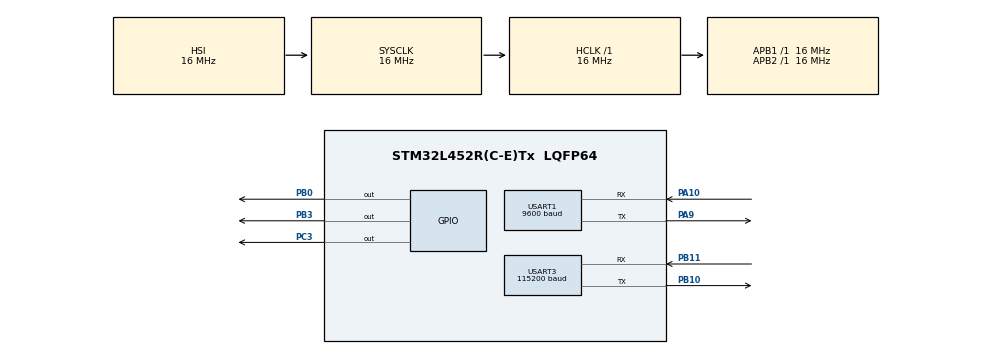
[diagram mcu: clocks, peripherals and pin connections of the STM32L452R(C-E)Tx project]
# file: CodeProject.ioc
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Mcu.Family=STM32L4
Mcu.Name=STM32L452R(C-E)Tx
Mcu.Package=LQFP64
NVIC.PriorityGroup=NVIC_PRIORITYGROUP_4
NVIC.TIM2_IRQn=true\:0\:0\:false\:false\:true\:true\:true
NVIC.USART1_IRQn=true\:0\:0\:false\:false\:true\:true\:true
NVIC.USART3_IRQn=true\:0\:0\:false\:false\:true\:true\:true
PA10.Mode=Asynchronous
PA10.Signal=USART1_RX
PA13\ (JTMS/SWDIO).Mode=Serial_Wire
PA13\ (JTMS/SWDIO).Signal=SYS_JTMS-SWDIO
PA14\ (JTCK/SWCLK).Mode=Serial_Wire
PA14\ (JTCK/SWCLK).Signal=SYS_JTCK-SWCLK
PA9.Mode=Asynchronous
PA9.Signal=USART1_TX
PB0.Signal=GPIO_Output
PB10.Mode=Asynchronous
PB10.Signal=USART3_TX
PB11.Mode=Asynchronous
PB11.Signal=USART3_RX
PB3\ (JTDO/TRACESWO).Signal=GPIO_Output
PC14-OSC32_IN\ (PC14).Mode=LSE-External-Oscillator
PC14-OSC32_IN\ (PC14).Signal=RCC_OSC32_IN
PC15-OSC32_OUT\ (PC15).Mode=LSE-External-Oscillator
PC15-OSC32_OUT\ (PC15).Signal=RCC_OSC32_OUT
PC3.Signal=GPIO_Output
ProjectManager.HeapSize=0x200
ProjectManager.StackSize=0x400
ProjectManager.TargetToolchain=STM32CubeIDE
RCC.ADCFreq_Value=64000000
RCC.AHBFreq_Value=16000000
RCC.APB1Freq_Value=16000000
RCC.APB1TimFreq_Value=16000000
RCC.APB2Freq_Value=16000000
RCC.APB2TimFreq_Value=16000000
RCC.CortexFreq_Value=16000000
RCC.HCLKFreq_Value=16000000
RCC.HSE_VALUE=8000000
RCC.HSI48_VALUE=48000000
RCC.HSI_VALUE=16000000
RCC.MSIClockRange=RCC_MSIRANGE_8
RCC.MSI_VALUE=16000000
RCC.PLLSourceVirtual=RCC_PLLSOURCE_HSI
RCC.RTCClockSelection=RCC_RTCCLKSOURCE_LSE
RCC.SYSCLKFreq_VALUE=16000000
RCC.SYSCLKSource=RCC_SYSCLKSOURCE_HSI
RCC.USBFreq_Value=64000000
RCC.VCOOutputFreq_Value=128000000
RTC.SynchPrediv=255
TIM2.Period=999
TIM2.Prescaler=15
USART1.BaudRate=9600
USART1.VirtualMode-Asynchronous=VM_ASYNC
USART3.BaudRate=115200
USART3.VirtualMode-Asynchronous=VM_ASYNC
VP_RTC_VS_RTC_Activate.Mode=RTC_Enabled
VP_RTC_VS_RTC_Calendar.Mode=RTC_Calendar
VP_TIM2_VS_ClockSourceINT.Mode=Internal
board=custom

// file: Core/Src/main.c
/* USER CODE BEGIN Header */
/**
  ******************************************************************************
  * @file           : main.c
  * @brief          : Main program body
  ******************************************************************************
  * @attention
  *
  * <h2><center>&copy; Copyright (c) 2021 STMicroelectronics.
  * All rights reserved.</center></h2>
  *
  * This software component is licensed by ST under BSD 3-Clause license,
  * the "License"; You may not use this file except in compliance with the
  * License. You may obtain a copy of the License at:
  *                        opensource.org/licenses/BSD-3-Clause
  *
  ******************************************************************************
  */
/* USER CODE END Header */

#include "main.h"

/* USER CODE BEGIN Includes */
#include "myLib.h"
#include "L506.h"
#include "string.h"
#include "time.h"
#include "UartRingbuffer.h"
/* USER CODE END Includes */

RTC_HandleTypeDef hrtc;

TIM_HandleTypeDef htim2;

UART_HandleTypeDef huart1;
UART_HandleTypeDef huart3;

/* USER CODE BEGIN PV */

uint8_t arrtime_rtc[256];
uint32_t Time_send_sv = 10;

/* USER CODE END PV */

void SystemClock_Config(void);
static void MX_GPIO_Init(void);
static void MX_USART1_UART_Init(void);
static void MX_TIM2_Init(void);
static void MX_USART3_UART_Init(void);
static void MX_RTC_Init(void);

int main(void)
{

  /* MCU Configuration--------------------------------------------------------*/

  /* Reset of all peripherals, Initializes the Flash interface and the Systick. */
  HAL_Init();

  /* Configure the system clock */
  SystemClock_Config();

  /* Initialize all configured peripherals */
  MX_GPIO_Init();
  MX_USART1_UART_Init();
  MX_TIM2_Init();
  MX_USART3_UART_Init();
  MX_RTC_Init();
  /* USER CODE BEGIN 2 */
//  HAL_UART_Receive_IT(&huart3, &data, 1);

  HAL_TIM_Base_Start_IT(&htim2);
  Ringbuf_init(huart3);

  /* USER CODE END 2 */

  /* Infinite loop */
  while (1)
  {

    /* USER CODE BEGIN 3 */
		Sim_work();
		Packet_Rtc_SendToServer(arrtime_rtc, strlen((char*)arrtime_rtc), Time_send_sv);
		// xu ly THB
		fncReceive_DataServer();

  }
  /* USER CODE END 3 */
}

void SystemClock_Config(void)
{
  RCC_OscInitTypeDef RCC_OscInitStruct = {0};
  RCC_ClkInitTypeDef RCC_ClkInitStruct = {0};
  RCC_PeriphCLKInitTypeDef PeriphClkInit = {0};

  /** Configure LSE Drive Capability
  */
  HAL_PWR_EnableBkUpAccess();
  __HAL_RCC_LSEDRIVE_CONFIG(RCC_LSEDRIVE_LOW);
  /** Initializes the RCC Oscillators according to the specified parameters
  * in the RCC_OscInitTypeDef structure.
  */
  RCC_OscInitStruct.OscillatorType = RCC_OSCILLATORTYPE_HSI|RCC_OSCILLATORTYPE_LSE;
  RCC_OscInitStruct.LSEState = RCC_LSE_ON;
  RCC_OscInitStruct.HSIState = RCC_HSI_ON;
  RCC_OscInitStruct.HSICalibrationValue = RCC_HSICALIBRATION_DEFAULT;
  RCC_OscInitStruct.PLL.PLLState = RCC_PLL_NONE;
  if (HAL_RCC_OscConfig(&RCC_OscInitStruct) != HAL_OK)
  {
    Error_Handler();
  }
  /** Initializes the CPU, AHB and APB buses clocks
  */
  RCC_ClkInitStruct.ClockType = RCC_CLOCKTYPE_HCLK|RCC_CLOCKTYPE_SYSCLK
                              |RCC_CLOCKTYPE_PCLK1|RCC_CLOCKTYPE_PCLK2;
  RCC_ClkInitStruct.SYSCLKSource = RCC_SYSCLKSOURCE_HSI;
  RCC_ClkInitStruct.AHBCLKDivider = RCC_SYSCLK_DIV1;
  RCC_ClkInitStruct.APB1CLKDivider = RCC_HCLK_DIV1;
  RCC_ClkInitStruct.APB2CLKDivider = RCC_HCLK_DIV1;

  if (HAL_RCC_ClockConfig(&RCC_ClkInitStruct, FLASH_LATENCY_0) != HAL_OK)
  {
    Error_Handler();
  }
  PeriphClkInit.PeriphClockSelection = RCC_PERIPHCLK_RTC|RCC_PERIPHCLK_USART1
                              |RCC_PERIPHCLK_USART3;
  PeriphClkInit.Usart1ClockSelection = RCC_USART1CLKSOURCE_PCLK2;
  PeriphClkInit.Usart3ClockSelection = RCC_USART3CLKSOURCE_PCLK1;
  PeriphClkInit.RTCClockSelection = RCC_RTCCLKSOURCE_LSE;
  if (HAL_RCCEx_PeriphCLKConfig(&PeriphClkInit) != HAL_OK)
  {
    Error_Handler();
  }
  /** Configure the main internal regulator output voltage
  */
  if (HAL_PWREx_ControlVoltageScaling(PWR_REGULATOR_VOLTAGE_SCALE1) != HAL_OK)
  {
    Error_Handler();
  }
}

static void MX_RTC_Init(void)
{

  RTC_TimeTypeDef sTime = {0};
  RTC_DateTypeDef sDate = {0};
  RTC_AlarmTypeDef sAlarm = {0};

  /** Initialize RTC Only
  */
  hrtc.Instance = RTC;
  hrtc.Init.HourFormat = RTC_HOURFORMAT_24;
  hrtc.Init.AsynchPrediv = 127;
  hrtc.Init.SynchPrediv = 255;
  hrtc.Init.OutPut = RTC_OUTPUT_DISABLE;
  hrtc.Init.OutPutRemap = RTC_OUTPUT_REMAP_NONE;
  hrtc.Init.OutPutPolarity = RTC_OUTPUT_POLARITY_HIGH;
  hrtc.Init.OutPutType = RTC_OUTPUT_TYPE_OPENDRAIN;
  if (HAL_RTC_Init(&hrtc) != HAL_OK)
  {
    Error_Handler();
  }

  /** Initialize RTC and set the Time and Date
  */
  sTime.Hours = 0;
  sTime.Minutes = 0;
  sTime.Seconds = 30;
  sTime.DayLightSaving = RTC_DAYLIGHTSAVING_NONE;
  sTime.StoreOperation = RTC_STOREOPERATION_RESET;
  if (HAL_RTC_SetTime(&hrtc, &sTime, RTC_FORMAT_BIN) != HAL_OK)
  {
    Error_Handler();
  }
  sDate.WeekDay = RTC_WEEKDAY_MONDAY;
  sDate.Month = RTC_MONTH_JANUARY;
  sDate.Date = 1;
  sDate.Year = 0;

  if (HAL_RTC_SetDate(&hrtc, &sDate, RTC_FORMAT_BIN) != HAL_OK)
  {
    Error_Handler();
  }
  /** Enable the Alarm A
  */
  sAlarm.AlarmTime.Hours = 1;
  sAlarm.AlarmTime.Minutes = 1;
  sAlarm.AlarmTime.Seconds = 10;
  sAlarm.AlarmTime.SubSeconds = 0;
  sAlarm.AlarmTime.DayLightSaving = RTC_DAYLIGHTSAVING_NONE;
  sAlarm.AlarmTime.StoreOperation = RTC_STOREOPERATION_RESET;
  sAlarm.AlarmMask = RTC_ALARMMASK_DATEWEEKDAY;
  sAlarm.AlarmSubSecondMask = RTC_ALARMSUBSECONDMASK_ALL;
  sAlarm.AlarmDateWeekDaySel = RTC_ALARMDATEWEEKDAYSEL_DATE;
  sAlarm.AlarmDateWeekDay = 1;
  sAlarm.Alarm = RTC_ALARM_A;
  if (HAL_RTC_SetAlarm_IT(&hrtc, &sAlarm, RTC_FORMAT_BIN) != HAL_OK)
  {
    Error_Handler();
  }

}

static void MX_TIM2_Init(void)
{

  TIM_ClockConfigTypeDef sClockSourceConfig = {0};
  TIM_MasterConfigTypeDef sMasterConfig = {0};

  htim2.Instance = TIM2;
  htim2.Init.Prescaler = 15;
  htim2.Init.CounterMode = TIM_COUNTERMODE_UP;
  htim2.Init.Period = 999;
  htim2.Init.ClockDivision = TIM_CLOCKDIVISION_DIV1;
  htim2.Init.AutoReloadPreload = TIM_AUTORELOAD_PRELOAD_DISABLE;
  if (HAL_TIM_Base_Init(&htim2) != HAL_OK)
  {
    Error_Handler();
  }
  sClockSourceConfig.ClockSource = TIM_CLOCKSOURCE_INTERNAL;
  if (HAL_TIM_ConfigClockSource(&htim2, &sClockSourceConfig) != HAL_OK)
  {
    Error_Handler();
  }
  sMasterConfig.MasterOutputTrigger = TIM_TRGO_RESET;
  sMasterConfig.MasterSlaveMode = TIM_MASTERSLAVEMODE_DISABLE;
  if (HAL_TIMEx_MasterConfigSynchronization(&htim2, &sMasterConfig) != HAL_OK)
  {
    Error_Handler();
  }

}

static void MX_USART1_UART_Init(void)
{

  huart1.Instance = USART1;
  huart1.Init.BaudRate = 9600;
  huart1.Init.WordLength = UART_WORDLENGTH_8B;
  huart1.Init.StopBits = UART_STOPBITS_1;
  huart1.Init.Parity = UART_PARITY_NONE;
  huart1.Init.Mode = UART_MODE_TX_RX;
  huart1.Init.HwFlowCtl = UART_HWCONTROL_NONE;
  huart1.Init.OverSampling = UART_OVERSAMPLING_16;
  huart1.Init.OneBitSampling = UART_ONE_BIT_SAMPLE_DISABLE;
  huart1.AdvancedInit.AdvFeatureInit = UART_ADVFEATURE_NO_INIT;
  if (HAL_UART_Init(&huart1) != HAL_OK)
  {
    Error_Handler();
  }

}

static void MX_USART3_UART_Init(void)
{

  huart3.Instance = USART3;
  huart3.Init.BaudRate = 115200;
  huart3.Init.WordLength = UART_WORDLENGTH_8B;
  huart3.Init.StopBits = UART_STOPBITS_1;
  huart3.Init.Parity = UART_PARITY_NONE;
  huart3.Init.Mode = UART_MODE_TX_RX;
  huart3.Init.HwFlowCtl = UART_HWCONTROL_NONE;
  huart3.Init.OverSampling = UART_OVERSAMPLING_16;
  huart3.Init.OneBitSampling = UART_ONE_BIT_SAMPLE_DISABLE;
  huart3.AdvancedInit.AdvFeatureInit = UART_ADVFEATURE_NO_INIT;
  if (HAL_UART_Init(&huart3) != HAL_OK)
  {
    Error_Handler();
  }

}

static void MX_GPIO_Init(void)
{
  GPIO_InitTypeDef GPIO_InitStruct = {0};

  /* GPIO Ports Clock Enable */
  __HAL_RCC_GPIOC_CLK_ENABLE();
  __HAL_RCC_GPIOB_CLK_ENABLE();
  __HAL_RCC_GPIOA_CLK_ENABLE();

  /*Configure GPIO pin Output Level */
  HAL_GPIO_WritePin(GPIOC, GPIO_PIN_3, GPIO_PIN_RESET);

  /*Configure GPIO pin Output Level */
  HAL_GPIO_WritePin(GPIOB, GPIO_PIN_0|GPIO_PIN_3, GPIO_PIN_RESET);

  /*Configure GPIO pin : PC3 */
  GPIO_InitStruct.Pin = GPIO_PIN_3;
  GPIO_InitStruct.Mode = GPIO_MODE_OUTPUT_PP;
  GPIO_InitStruct.Pull = GPIO_NOPULL;
  GPIO_InitStruct.Speed = GPIO_SPEED_FREQ_LOW;
  HAL_GPIO_Init(GPIOC, &GPIO_InitStruct);

  /*Configure GPIO pins : PB0 PB3 */
  GPIO_InitStruct.Pin = GPIO_PIN_0|GPIO_PIN_3;
  GPIO_InitStruct.Mode = GPIO_MODE_OUTPUT_PP;
  GPIO_InitStruct.Pull = GPIO_NOPULL;
  GPIO_InitStruct.Speed = GPIO_SPEED_FREQ_LOW;
  HAL_GPIO_Init(GPIOB, &GPIO_InitStruct);

}

///* USER CODE BEGIN 4 */
//void HAL_UART_RxCpltCallback(UART_HandleTypeDef *huart)
//{
//	if(huart->Instance == USART3)
//	{
//		if(data != 0){
//		buffer[indexBuffer] = data;//thay buffer bang ring buffer
//		indexBuffer++;
//		//HAL_UART_Transmit_IT(&huart1, (uint8_t *)&Data, 1);
//		HAL_UART_Receive_IT(&huart3, &data, 1);
//		}
//	}
//}

/* USER CODE END 4 */

void Error_Handler(void)
{
}

/************************ (C) COPYRIGHT STMicroelectronics *****END OF FILE****/
